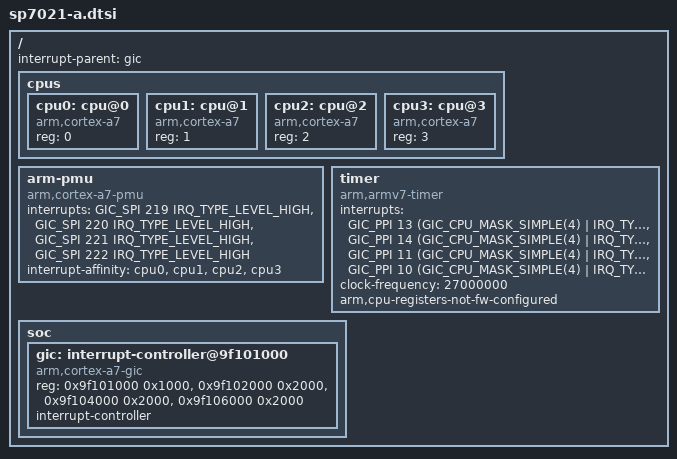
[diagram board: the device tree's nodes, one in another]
// SPDX-License-Identifier: GPL-2.0-or-later OR BSD-2-Clause
/*
 * SunPlus Plus1 SP7021 A-Chip (CA7)
 *
 * Copyright (c) 2020 Andreas Färber
 */

#include <dt-bindings/interrupt-controller/arm-gic.h>

#include "sp7021.dtsi"

/ {
	interrupt-parent = <&gic>;

	cpus {
		#address-cells = <1>;
		#size-cells = <0>;

		cpu0: cpu@0 {
			device_type = "cpu";
			compatible = "arm,cortex-a7";
			reg = <0>;
		};

		cpu1: cpu@1{
			device_type = "cpu";
			compatible = "arm,cortex-a7";
			reg = <1>;
		};

		cpu2: cpu@2 {
			device_type = "cpu";
			compatible = "arm,cortex-a7";
			reg = <2>;
		};

		cpu3: cpu@3 {
			device_type = "cpu";
			compatible = "arm,cortex-a7";
			reg = <3>;
		};
	};

	arm-pmu {
		compatible = "arm,cortex-a7-pmu";
		interrupts = <GIC_SPI 219 IRQ_TYPE_LEVEL_HIGH>,
			     <GIC_SPI 220 IRQ_TYPE_LEVEL_HIGH>,
			     <GIC_SPI 221 IRQ_TYPE_LEVEL_HIGH>,
			     <GIC_SPI 222 IRQ_TYPE_LEVEL_HIGH>;
		interrupt-affinity = <&cpu0>, <&cpu1>, <&cpu2>, <&cpu3>;
	};

	timer: timer {
		compatible = "arm,armv7-timer";
		interrupts = <GIC_PPI 13 (GIC_CPU_MASK_SIMPLE(4) | IRQ_TYPE_LEVEL_LOW)>,
			     <GIC_PPI 14 (GIC_CPU_MASK_SIMPLE(4) | IRQ_TYPE_LEVEL_LOW)>,
			     <GIC_PPI 11 (GIC_CPU_MASK_SIMPLE(4) | IRQ_TYPE_LEVEL_LOW)>,
			     <GIC_PPI 10 (GIC_CPU_MASK_SIMPLE(4) | IRQ_TYPE_LEVEL_LOW)>;
		clock-frequency = <27000000>;
		arm,cpu-registers-not-fw-configured;
	};

	soc {
		gic: interrupt-controller@9f101000 {
			compatible = "arm,cortex-a7-gic";
			reg = <0x9f101000 0x1000>,
			      <0x9f102000 0x2000>,
			      <0x9f104000 0x2000>,
			      <0x9f106000 0x2000>;
			interrupt-controller;
			#interrupt-cells = <3>;
		};
	};
};
